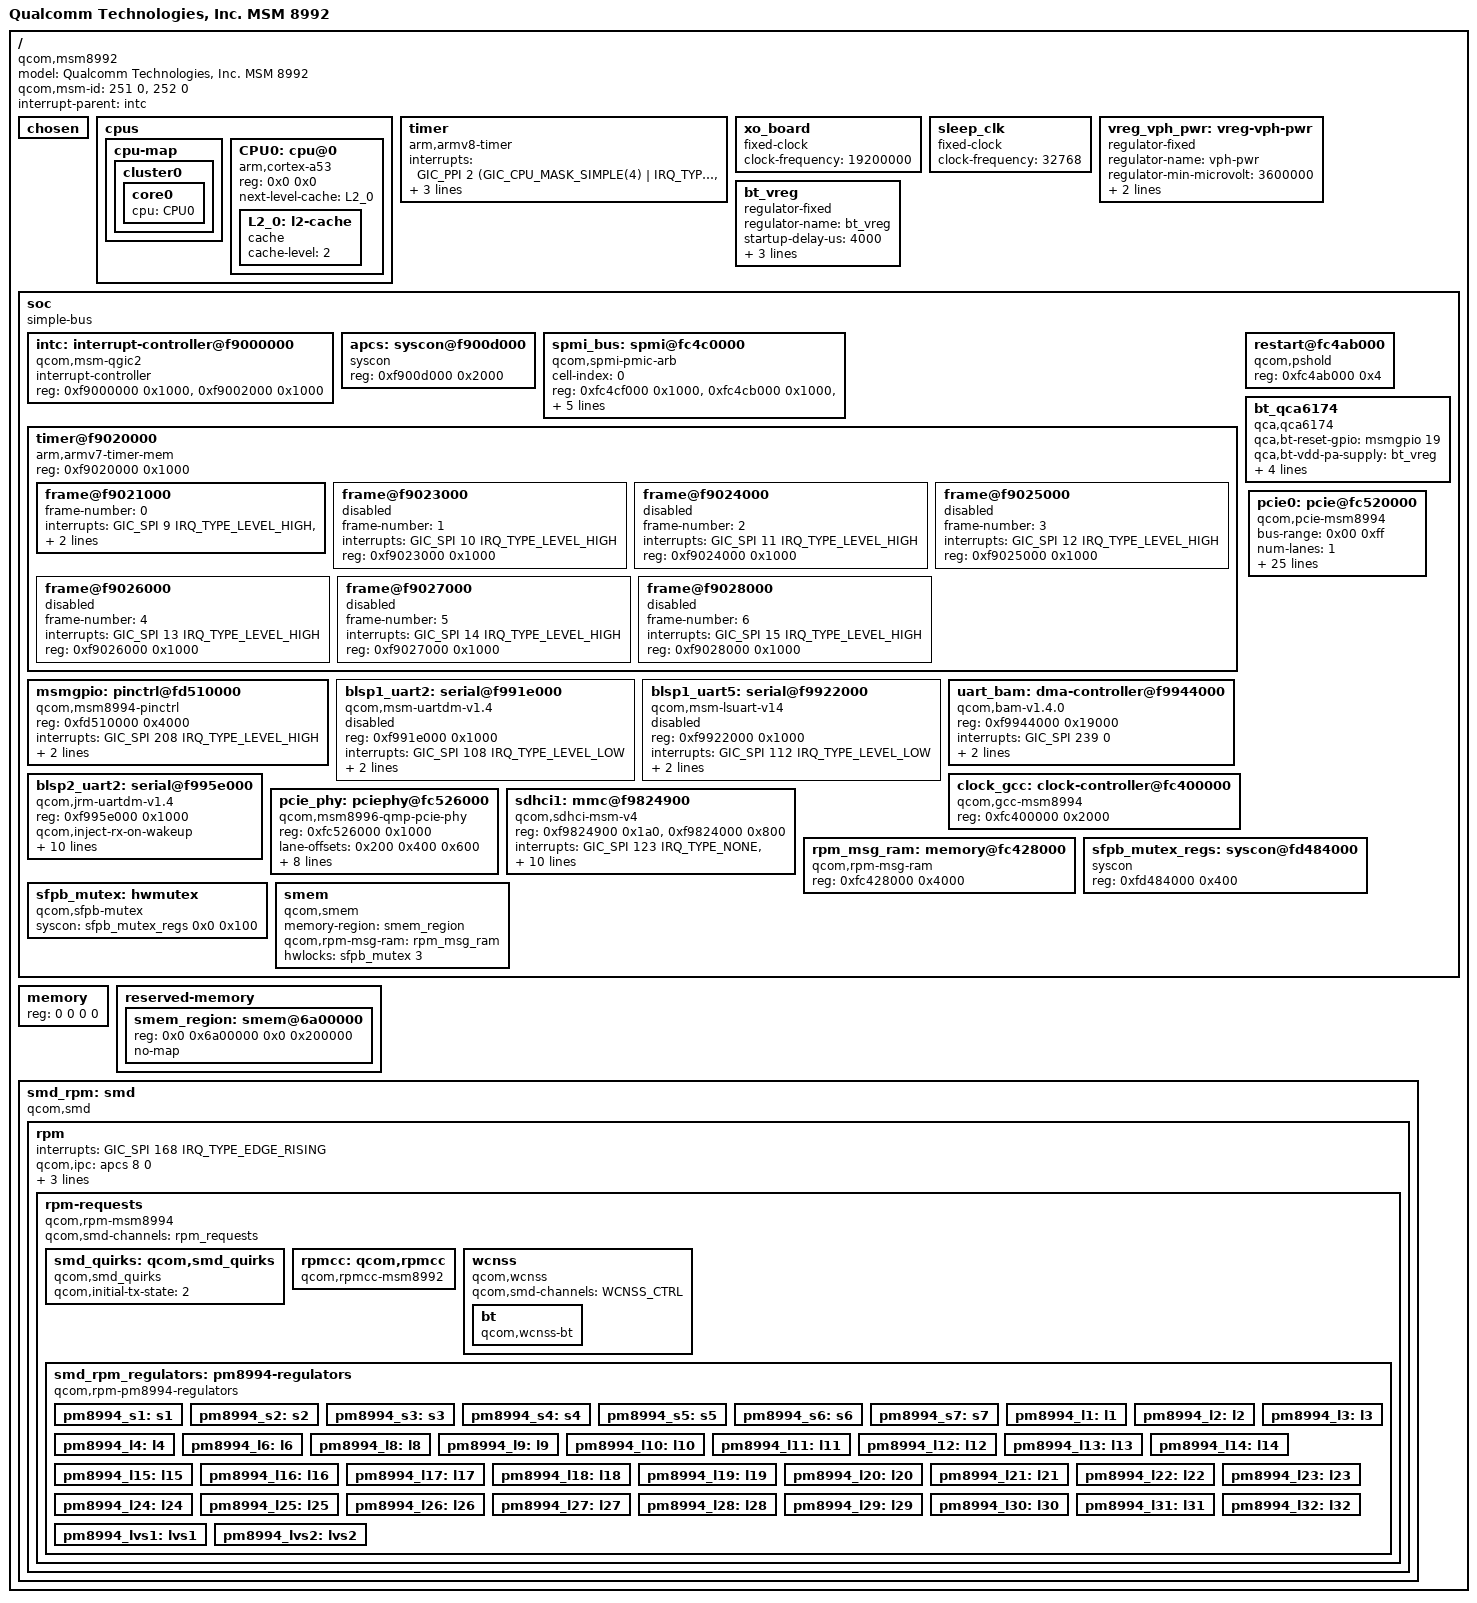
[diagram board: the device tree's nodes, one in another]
/* Copyright (c) 2013-2016, The Linux Foundation. All rights reserved.
 *
 * This program is free software; you can redistribute it and/or modify
 * it under the terms of the GNU General Public License version 2 and
 * only version 2 as published by the Free Software Foundation.
 *
 * This program is distributed in the hope that it will be useful,
 * but WITHOUT ANY WARRANTY; without even the implied warranty of
 * MERCHANTABILITY or FITNESS FOR A PARTICULAR PURPOSE.  See the
 * GNU General Public License for more details.
 */

#include <dt-bindings/interrupt-controller/arm-gic.h>
#include <dt-bindings/clock/qcom,gcc-msm8994.h>
#include <dt-bindings/clock/qcom,rpmcc.h>
#include <dt-bindings/gpio/gpio.h>

/ {
	model = "Qualcomm Technologies, Inc. MSM 8992";
	compatible = "qcom,msm8992";
	// msm-id needed by bootloader for selecting correct blob
	qcom,msm-id = <251 0>, <252 0>;
	interrupt-parent = <&intc>;

	#address-cells = <2>;
	#size-cells = <2>;

	chosen { };

	cpus {
		#address-cells = <2>;
		#size-cells = <0>;
		cpu-map {
			cluster0 {
				core0 {
					cpu = <&CPU0>;
				};
			};
		};

		CPU0: cpu@0 {
			device_type = "cpu";
			compatible = "arm,cortex-a53", "arm,armv8";
			reg = <0x0 0x0>;
			next-level-cache = <&L2_0>;
			L2_0: l2-cache {
				compatible = "cache";
				cache-level = <2>;
			};
		};
	};

	timer {
		compatible = "arm,armv8-timer";
		interrupts = <GIC_PPI 2 (GIC_CPU_MASK_SIMPLE(4) | IRQ_TYPE_LEVEL_LOW)>,
			     <GIC_PPI 3 (GIC_CPU_MASK_SIMPLE(4) | IRQ_TYPE_LEVEL_LOW)>,
			     <GIC_PPI 4 (GIC_CPU_MASK_SIMPLE(4) | IRQ_TYPE_LEVEL_LOW)>,
			     <GIC_PPI 1 (GIC_CPU_MASK_SIMPLE(4) | IRQ_TYPE_LEVEL_LOW)>;
	};

	xo_board: xo_board {
		compatible = "fixed-clock";
		#clock-cells = <0>;
		clock-frequency = <19200000>;
	};

	sleep_clk: sleep_clk {
		compatible = "fixed-clock";
		#clock-cells = <0>;
		clock-frequency = <32768>;
	};

	vreg_vph_pwr: vreg-vph-pwr {
		compatible = "regulator-fixed";
		status = "okay";
		regulator-name = "vph-pwr";

		regulator-min-microvolt = <3600000>;
		regulator-max-microvolt = <3600000>;

		regulator-always-on;
	};


	bt_vreg: bt_vreg {
                compatible = "regulator-fixed";
                regulator-name = "bt_vreg";
                startup-delay-us = <4000>;
                enable-active-high;
                gpio = <&msmgpio 9 GPIO_ACTIVE_LOW>;
		regulator-always-on;  /* JRM XXX dont submit this line */
		status = "okay";
        };

	soc {
		#address-cells = <1>;
		#size-cells = <1>;
		ranges = <0 0 0 0xffffffff>;
		compatible = "simple-bus";

		intc: interrupt-controller@f9000000 {
			compatible = "qcom,msm-qgic2";
			interrupt-controller;
			#interrupt-cells = <3>;
			reg = <0xf9000000 0x1000>,
				<0xf9002000 0x1000>;
		};

		apcs: syscon@f900d000 {
			compatible = "syscon";
			reg = <0xf900d000 0x2000>;
		};

		spmi_bus: spmi@fc4c0000 {
			cell-index = <0>;
			compatible = "qcom,spmi-pmic-arb";
			reg-names = "core", "intr", "cnfg";
			reg = <0xfc4cf000 0x1000>,
				<0xfc4cb000 0x1000>,
				<0xfc4ca000 0x1000>;
			interrupts = <0 190 0>; /* ee0_krait_hlos_spmi_periph_irq */
			qcom,pmic-arb-channel = <0>;
			qcom,pmic-arb-ee = <0>;
			#interrupt-cells = <3>;
			interrupt-controller;
		};

		timer@f9020000 {
			#address-cells = <1>;
			#size-cells = <1>;
			ranges;
			compatible = "arm,armv7-timer-mem";
			reg = <0xf9020000 0x1000>;

			frame@f9021000 {
				frame-number = <0>;
				interrupts = <GIC_SPI 9 IRQ_TYPE_LEVEL_HIGH>,
						<GIC_SPI 8 IRQ_TYPE_LEVEL_HIGH>;
				reg = <0xf9021000 0x1000>,
					<0xf9022000 0x1000>;
			};

			frame@f9023000 {
				frame-number = <1>;
				interrupts = <GIC_SPI 10 IRQ_TYPE_LEVEL_HIGH>;
				reg = <0xf9023000 0x1000>;
				status = "disabled";
			};

			frame@f9024000 {
				frame-number = <2>;
				interrupts = <GIC_SPI 11 IRQ_TYPE_LEVEL_HIGH>;
				reg = <0xf9024000 0x1000>;
				status = "disabled";
			};

			frame@f9025000 {
				frame-number = <3>;
				interrupts = <GIC_SPI 12 IRQ_TYPE_LEVEL_HIGH>;
				reg = <0xf9025000 0x1000>;
				status = "disabled";
			};

			frame@f9026000 {
				frame-number = <4>;
				interrupts = <GIC_SPI 13 IRQ_TYPE_LEVEL_HIGH>;
				reg = <0xf9026000 0x1000>;
				status = "disabled";
			};

			frame@f9027000 {
				frame-number = <5>;
				interrupts = <GIC_SPI 14 IRQ_TYPE_LEVEL_HIGH>;
				reg = <0xf9027000 0x1000>;
				status = "disabled";
			};

			frame@f9028000 {
				frame-number = <6>;
				interrupts = <GIC_SPI 15 IRQ_TYPE_LEVEL_HIGH>;
				reg = <0xf9028000 0x1000>;
				status = "disabled";
			};
		};

		restart@fc4ab000 {
			compatible = "qcom,pshold";
			reg = <0xfc4ab000 0x4>;
		};

		msmgpio: pinctrl@fd510000 {
			compatible = "qcom,msm8994-pinctrl";
			reg = <0xfd510000 0x4000>;
			interrupts = <GIC_SPI 208 IRQ_TYPE_LEVEL_HIGH>;
			gpio-controller;
			#gpio-cells = <2>;
			interrupt-controller;
			#interrupt-cells = <2>;
		};

		blsp1_uart2: serial@f991e000 {
			compatible = "qcom,msm-uartdm-v1.4", "qcom,msm-uartdm";
			reg = <0xf991e000 0x1000>;
			interrupts = <GIC_SPI 108 IRQ_TYPE_LEVEL_LOW>;
			status = "disabled";
			clock-names = "core", "iface";
			clocks = <&clock_gcc GCC_BLSP1_UART2_APPS_CLK>,
				<&clock_gcc GCC_BLSP1_AHB_CLK>;
		};

		blsp1_uart5: serial@f9922000 {
			compatible = "qcom,msm-lsuart-v14", "qcom,msm-uartdm";
			reg = <0xf9922000 0x1000>;
			interrupts = <GIC_SPI 112 IRQ_TYPE_LEVEL_LOW>;
			status = "disabled";
			clock-names = "core", "iface";
			clocks = <&clock_gcc GCC_BLSP1_UART5_APPS_CLK>,
				<&clock_gcc GCC_BLSP1_AHB_CLK>;
		};

		uart_bam: dma-controller@f9944000 { /* BLSP2 */
			compatible = "qcom,bam-v1.4.0";
			reg = <0xf9944000 0x19000>;
			interrupts = <GIC_SPI 239 0>;
			clocks = <&clock_gcc GCC_BAM_DMA_AHB_CLK>;
			clock-names = "bam_clk";
			#dma-cells = <4>;
			qcom,ee = <0>;
		};

	/*** BAM on the 8992 is v1.6.2 but 1.4.0 compatible string should
	still work */

	/* f995e000.uart: ttyHS0 at MMIO 0xf995e000 (irq = 146) is a MSM HS UART */
        blsp2_uart2: serial@f995e000 {
		compatible = "qcom,jrm-uartdm-v1.4", "qcom,jrm-uartdm";
		/*compatible = "qcom,msm-hsuart-v14"; */
                reg = <0xf995e000 0x1000>;
                        /*<0xf9944000 0x19000>; */
                reg-names = "core_mem"; /* "bam_mem"; */
		qcom,inject-rx-on-wakeup;
		qcom,rx-char-to-inject = <0xFD>;
		qcom,bam-tx-ep-pipe-index = <2>;
		qcom,bam-rx-ep-pipe-index = <3>;
		qcom,master-id = <84>;
	
		interrupts = <GIC_SPI 146 IRQ_TYPE_LEVEL_LOW>;

		/***
				<GIC_SPI 271 IRQ_TYPE_LEVEL_LOW>,
				<GIC_SPI 448 IRQ_TYPE_EDGE_FALLING>;
		interrupt-names = "core_irq", "bam_irq", "wakeup_irq";

                clock-names = "core_clk", "iface_clk";
		****/
		clock-names = "core", "iface";
                clocks = <&clock_gcc GCC_BLSP2_UART2_APPS_CLK>,
                        <&clock_gcc GCC_BLSP2_AHB_CLK>;

		pinctrl-names = "sleep", "default";
		pinctrl-0 = <&blsp2_uart2_sleep>;
		pinctrl-1 = <&blsp2_uart2_default>;

		dmas = <&uart_bam 3>, <&uart_bam 2>;
		dma-names = "rx", "tx";
                status = "okay";
        };

	bt_qca6174 {
                compatible = "qca,qca6174";
                qca,bt-reset-gpio = <&msmgpio 19 GPIO_ACTIVE_HIGH>; /* BT_EN */
                qca,bt-vdd-pa-supply = <&bt_vreg>;
                qca,bt-vdd-io-supply = <&pm8994_s4>;
                qca,bt-vdd-xtal-supply = <&pm8994_l30>;
                qca,bt-vdd-io-voltage-level = <1800000 1800000>;
                qca,bt-vdd-xtal-voltage-level = <1800000 1800000>;
        };
			
		clock_gcc: clock-controller@fc400000 {
			compatible = "qcom,gcc-msm8994";
			#clock-cells = <1>;
			#reset-cells = <1>;
			#power-domain-cells = <1>;
			reg = <0xfc400000 0x2000>;
		};

		pcie_phy: pciephy@fc526000 {
			compatible = "qcom,msm8996-qmp-pcie-phy";  /* not sure if this is ok */
			/* common base = 526000
				tx = 526200
				rx = 526400
				pcs = 526600
			*/

			reg = <0xfc526000 0x1000>;

			lane-offsets = <0x200 0x400 0x600>;
			#phy-cells = <1>;

			clocks = <&clock_gcc PCIE_0_AUX_CLK_SRC>,
				<&clock_gcc GCC_PCIE_0_CFG_AHB_CLK>, /* clk_gcc_pcie_0_cfg_ahb_clk */
				<&rpmcc MSM8992_RPM_SMD_LN_BB_CLK>,
				<&clock_gcc GCC_PCIE_CLKREF_CLK>;
				/*<&clock_gcc GCC_PCIE_0_PIPE_CLK>;*/

			clock-names = "aux",
					"cfg_ahb",
					"ref_clk_src",
					"ref_clk";
					/*"pipe0";*/
			vdda-phy-supply = <&pm8994_l28>;
			vdda-pll-supply = <&pm8994_l12>;

			resets = <&clock_gcc GCC_PCIE_PHY_0_PHY_BCR>,
				<&clock_gcc GCC_PCIE_PHY_0_BCR>;
				/* <&gcc GCC_PCIE_0_PHY_BCR>, dont know what the value should be for this
				<&clock_gcc GCC_PCIE_PHY_COM_NOCSR_BCR>; */	

			reset-names = "phy", "common"; /* Double check names */
		};
				

        pcie0: pcie@fc520000 {
                compatible = "qcom,pcie-msm8994";
		status = "okay";
		/* power-domains = <&clock_gcc PCIE_GDSC>; ???? */
		bus-range = <0x00 0xff>;
		num-lanes = <1>;

                reg = <0xfc520000 0x2000>,
                      /* <0xfc526000 0x1000>, phy */
                      <0xff000000 0xf1d>,  /*dbi (3.10=dm_core)*/
                      <0xff000f20 0xa8>,  /*elbi*/
                      <0xff100000 0x100000>; /*config*/

                reg-names = "parf", "dbi", "elbi", "config";

		phys = <&pcie_phy 0>;
		phy-names = "pciephy";

		#address-cells = <3>;
		#size-cells = <2>;
		ranges = <0x01000000 0x0 0xff200000 0xff200000 0x0 0x0100000>,
			<0x02000000 0x0 0xff300000 0xff300000 0x0 0xd00000>;

                /*interrupt-parent = <&pcie0>; */
                interrupts = <GIC_SPI 243 IRQ_TYPE_NONE>;

                interrupt-names = "msi";
                #interrupt-cells = <1>;
                interrupt-map-mask = <0 0 0 0x7>;
		interrupt-map = <0 0 0 1 &intc 0 244 IRQ_TYPE_NONE>,
                                <0 0 0 2 &intc 0 245 IRQ_TYPE_NONE>,
                                <0 0 0 3 &intc 0 247 IRQ_TYPE_NONE>,
                                <0 0 0 4 &intc 0 248 IRQ_TYPE_NONE>;


                pinctrl-names = "default", "sleep";
                pinctrl-0 = <&pcie0_clkreq_default &pcie0_perst_default &pcie0_wake_default>;
                pinctrl-1 = <&pcie0_clkreq_default &pcie0_perst_default &pcie0_wake_sleep>;

                perst-gpio = <&msmgpio 35 GPIO_ACTIVE_LOW>;
                wake-gpio = <&msmgpio 37 GPIO_ACTIVE_LOW>;

                /* gdsc-vdd-supply = <&gdsc_pcie_0>;
                vreg-1.8-supply = <&pm8994_l12>; */
                vdda-supply = <&pm8994_l28>;

		linux,pci-domain = <0>;

                qcom,msi-gicm-addr = <0xf9006040>;
                qcom,msi-gicm-base = <0x180>;

                clocks = <&clock_gcc PCIE_0_PIPE_CLK_SRC>,
                        <&clock_gcc PCIE_0_AUX_CLK_SRC>,
                        <&clock_gcc GCC_PCIE_0_CFG_AHB_CLK>,
                        <&clock_gcc GCC_PCIE_0_MSTR_AXI_CLK>,
                        <&clock_gcc GCC_PCIE_0_SLV_AXI_CLK>;

                clock-names = "pipe",
				"aux",
				"cfg",
				"bus_master",
				"bus_slave";

        };

		sdhci1: mmc@f9824900 {
			compatible = "qcom,sdhci-msm-v4";
			reg = <0xf9824900 0x1a0>, <0xf9824000 0x800>;
			reg-names = "hc_mem", "core_mem";

			interrupts = <GIC_SPI 123 IRQ_TYPE_NONE>,
					<GIC_SPI 138 IRQ_TYPE_NONE>;
			interrupt-names = "hc_irq", "pwr_irq";

			clocks = <&clock_gcc GCC_SDCC1_APPS_CLK>,
				<&clock_gcc GCC_SDCC1_AHB_CLK>;
			clock-names = "core", "iface";

			pinctrl-names = "default", "sleep";
			pinctrl-0 = <&sdc1_clk_on &sdc1_cmd_on &sdc1_data_on
					&sdc1_rclk_on>;
			pinctrl-1 = <&sdc1_clk_off &sdc1_cmd_off &sdc1_data_off
					&sdc1_rclk_off>;

			regulator-always-on;
			bus-width = <8>;
			mmc-hs400-1_8v;
			status = "okay";
		};

		rpm_msg_ram: memory@fc428000 {
			compatible = "qcom,rpm-msg-ram";
			reg = <0xfc428000 0x4000>;
		};

		sfpb_mutex_regs: syscon@fd484000 {
			#address-cells = <1>;
			#size-cells = <1>;
			compatible = "syscon";
			reg = <0xfd484000 0x400>;
		};

		sfpb_mutex: hwmutex {
			compatible = "qcom,sfpb-mutex";
			syscon = <&sfpb_mutex_regs 0x0 0x100>;
			#hwlock-cells = <1>;
		};

		smem {
			compatible = "qcom,smem";
			memory-region = <&smem_region>;
			qcom,rpm-msg-ram = <&rpm_msg_ram>;
			hwlocks = <&sfpb_mutex 3>;
		};
	};

	memory {
		device_type = "memory";
		reg = <0 0 0 0>; // bootloader will update
	};

	reserved-memory {
		#address-cells = <2>;
		#size-cells = <2>;
		ranges;

		smem_region: smem@6a00000 {
			reg = <0x0 0x6a00000 0x0 0x200000>;
			no-map;
		};
	};

	smd_rpm: smd {
		compatible = "qcom,smd";
		rpm {
			interrupts = <GIC_SPI 168 IRQ_TYPE_EDGE_RISING>;
			qcom,ipc = <&apcs 8 0>;
			qcom,smd-edge = <15>;
			qcom,local-pid = <0>;
			qcom,remote-pid = <6>;

			rpm-requests {
				compatible = "qcom,rpm-msm8994";
				qcom,smd-channels = "rpm_requests";

				smd_quirks: qcom,smd_quirks {
					compatible = "qcom,smd_quirks";
					qcom,initial-tx-state = <2>;
				};

				rpmcc: qcom,rpmcc {
					/* TODO: update when rpmcc-msm8994 support added */
					compatible = "qcom,rpmcc-msm8992", "qcom,rpmcc";
					#clock-cells = <1>;
				};


				wcnss {
					compatible = "qcom,wcnss";
					qcom,smd-channels = "WCNSS_CTRL";

					#address-cells = <1>;
					#size-cells = <1>;

					bt {
						compatible = "qcom,wcnss-bt";
					};
				};
				smd_rpm_regulators: pm8994-regulators {
					compatible = "qcom,rpm-pm8994-regulators";

					pm8994_s1: s1 {};
					pm8994_s2: s2 {};
					pm8994_s3: s3 {};
					pm8994_s4: s4 {};
					pm8994_s5: s5 {};
					pm8994_s6: s6 {};
					pm8994_s7: s7 {};

					pm8994_l1: l1 {};
					pm8994_l2: l2 {};
					pm8994_l3: l3 {};
					pm8994_l4: l4 {};
					pm8994_l6: l6 {};
					pm8994_l8: l8 {};
					pm8994_l9: l9 {};
					pm8994_l10: l10 {};
					pm8994_l11: l11 {};
					pm8994_l12: l12 {};
					pm8994_l13: l13 {};
					pm8994_l14: l14 {};
					pm8994_l15: l15 {};
					pm8994_l16: l16 {};
					pm8994_l17: l17 {};
					pm8994_l18: l18 {};
					pm8994_l19: l19 {};
					pm8994_l20: l20 {};
					pm8994_l21: l21 {};
					pm8994_l22: l22 {};
					pm8994_l23: l23 {};
					pm8994_l24: l24 {};
					pm8994_l25: l25 {};
					pm8994_l26: l26 {};
					pm8994_l27: l27 {};
					pm8994_l28: l28 {};
					pm8994_l29: l29 {};
					pm8994_l30: l30 {};
					pm8994_l31: l31 {};
					pm8994_l32: l32 {};

					pm8994_lvs1: lvs1 {};
					pm8994_lvs2: lvs2 {};
				};
			};
		};
	};
};

#include "msm8992-pins.dtsi"
#include "msm8994-smd-rpm.dtsi"

/*#include "msm-pm8994.dtsi"*/
#include "msm-pmi8994.dtsi"
